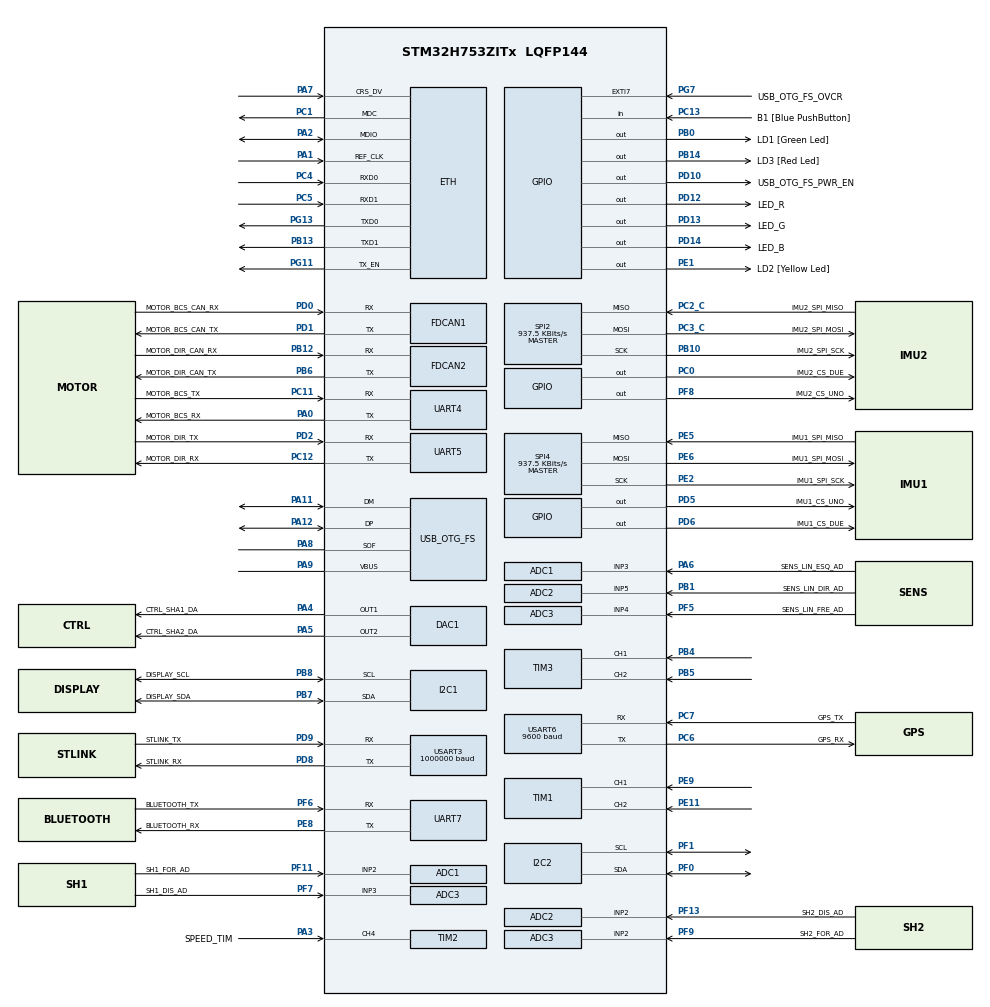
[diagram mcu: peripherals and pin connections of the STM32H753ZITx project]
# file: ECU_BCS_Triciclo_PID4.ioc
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ADC1.Channel-0\#ChannelRegularConversion=ADC_CHANNEL_2
ADC1.ClockPrescaler=ADC_CLOCK_ASYNC_DIV4
ADC1.NbrOfConversionFlag=1
ADC1.OffsetNumber-0\#ChannelRegularConversion=ADC_OFFSET_NONE
ADC1.OffsetSignedSaturation-0\#ChannelRegularConversion=DISABLE
ADC1.Rank-0\#ChannelRegularConversion=1
ADC1.SamplingTime-0\#ChannelRegularConversion=ADC_SAMPLETIME_1CYCLE_5
ADC1.master=1
ADC2.Channel-0\#ChannelRegularConversion=ADC_CHANNEL_2
ADC2.ClockPrescaler=ADC_CLOCK_ASYNC_DIV4
ADC2.NbrOfConversionFlag=1
ADC2.OffsetNumber-0\#ChannelRegularConversion=ADC_OFFSET_NONE
ADC2.OffsetSignedSaturation-0\#ChannelRegularConversion=DISABLE
ADC2.Rank-0\#ChannelRegularConversion=1
ADC2.SamplingTime-0\#ChannelRegularConversion=ADC_SAMPLETIME_1CYCLE_5
ADC3.Channel-0\#ChannelRegularConversion=ADC_CHANNEL_2
ADC3.ClockPrescaler=ADC_CLOCK_ASYNC_DIV4
ADC3.NbrOfConversionFlag=1
ADC3.OffsetNumber-0\#ChannelRegularConversion=ADC_OFFSET_NONE
ADC3.OffsetSignedSaturation-0\#ChannelRegularConversion=DISABLE
ADC3.Rank-0\#ChannelRegularConversion=1
ADC3.SamplingTime-0\#ChannelRegularConversion=ADC_SAMPLETIME_1CYCLE_5
CORTEX_M7.CPU_DCache=Disabled
CORTEX_M7.CPU_ICache=Disabled
CORTEX_M7.MPU_Control=__NULL
DAC1.DAC_Channel-DAC_OUT1=DAC_CHANNEL_1
DAC1.DAC_Channel-DAC_OUT2=DAC_CHANNEL_2
Dma.Request0=SPI4_RX
Dma.Request1=SPI4_TX
Dma.SPI4_RX.0.Direction=DMA_PERIPH_TO_MEMORY
Dma.SPI4_RX.0.EventEnable=DISABLE
Dma.SPI4_RX.0.FIFOMode=DMA_FIFOMODE_DISABLE
Dma.SPI4_RX.0.Instance=DMA1_Stream0
Dma.SPI4_RX.0.MemDataAlignment=DMA_MDATAALIGN_WORD
Dma.SPI4_RX.0.MemInc=DMA_MINC_ENABLE
Dma.SPI4_RX.0.Mode=DMA_NORMAL
Dma.SPI4_RX.0.PeriphDataAlignment=DMA_PDATAALIGN_WORD
Dma.SPI4_RX.0.PeriphInc=DMA_PINC_DISABLE
Dma.SPI4_RX.0.Polarity=HAL_DMAMUX_REQ_GEN_RISING
Dma.SPI4_RX.0.Priority=DMA_PRIORITY_LOW
Dma.SPI4_RX.0.RequestNumber=1
Dma.SPI4_RX.0.SignalID=NONE
Dma.SPI4_RX.0.SyncEnable=DISABLE
Dma.SPI4_RX.0.SyncPolarity=HAL_DMAMUX_SYNC_NO_EVENT
Dma.SPI4_RX.0.SyncRequestNumber=1
Dma.SPI4_RX.0.SyncSignalID=NONE
Dma.SPI4_TX.1.Direction=DMA_MEMORY_TO_PERIPH
Dma.SPI4_TX.1.EventEnable=DISABLE
Dma.SPI4_TX.1.FIFOMode=DMA_FIFOMODE_DISABLE
Dma.SPI4_TX.1.Instance=DMA1_Stream1
Dma.SPI4_TX.1.MemDataAlignment=DMA_MDATAALIGN_WORD
Dma.SPI4_TX.1.MemInc=DMA_MINC_ENABLE
Dma.SPI4_TX.1.Mode=DMA_NORMAL
Dma.SPI4_TX.1.PeriphDataAlignment=DMA_PDATAALIGN_WORD
Dma.SPI4_TX.1.PeriphInc=DMA_PINC_DISABLE
Dma.SPI4_TX.1.Polarity=HAL_DMAMUX_REQ_GEN_RISING
Dma.SPI4_TX.1.Priority=DMA_PRIORITY_LOW
Dma.SPI4_TX.1.RequestNumber=1
Dma.SPI4_TX.1.SignalID=NONE
Dma.SPI4_TX.1.SyncEnable=DISABLE
Dma.SPI4_TX.1.SyncPolarity=HAL_DMAMUX_SYNC_NO_EVENT
Dma.SPI4_TX.1.SyncRequestNumber=1
Dma.SPI4_TX.1.SyncSignalID=NONE
ETH.ETH_RX_DESC_CNT=4
ETH.ETH_TX_DESC_CNT=4
ETH.MACAddr=00\:80\:E1\:00\:00\:00
ETH.MediaInterface=HAL_ETH_RMII_MODE
ETH.RxBuffAddress=0x30040200
ETH.RxBuffLen=1524
ETH.RxDescAddress=0x30040000
ETH.TxDescAddress=0x30040060
FDCAN1.AutoRetransmission=DISABLE
FDCAN1.CalculateBaudRateNominal=250000
FDCAN1.CalculateTimeBitNominal=4000
FDCAN1.CalculateTimeQuantumNominal=250.0
FDCAN1.DataPrescaler=25
FDCAN1.DataSyncJumpWidth=1
FDCAN1.DataTimeSeg1=2
FDCAN1.DataTimeSeg2=1
FDCAN1.NominalPrescaler=20
FDCAN1.NominalSyncJumpWidth=13
FDCAN1.NominalTimeSeg1=13
FDCAN1.RxFifo0ElmtsNbr=6
FDCAN1.StdFiltersNbr=1
FDCAN1.TxBuffersNbr=0
FDCAN1.TxFifoQueueElmtsNbr=6
FDCAN1.TxFifoQueueMode=FDCAN_TX_FIFO_OPERATION
FDCAN2.AutoRetransmission=ENABLE
FDCAN2.CalculateBaudRateNominal=250000
FDCAN2.CalculateTimeBitNominal=4000
FDCAN2.CalculateTimeQuantumNominal=250.0
FDCAN2.DataPrescaler=25
FDCAN2.DataSyncJumpWidth=1
FDCAN2.DataTimeSeg1=2
FDCAN2.MessageRAMOffset=1024
FDCAN2.NominalPrescaler=20
FDCAN2.NominalSyncJumpWidth=13
FDCAN2.NominalTimeSeg1=13
FDCAN2.RxFifo0ElmtsNbr=1
FDCAN2.StdFiltersNbr=1
FDCAN2.TxBuffersNbr=0
FDCAN2.TxFifoQueueElmtsNbr=1
FREERTOS.Queues01=lcdMessageQueue,16,lcdMessage_t,0,Static,lcdMessageQueueBuffer,lcdMessageQueueControlBlock
FREERTOS.Tasks01=defaultTask,24,128,StartDefaultTask,As weak,NULL,Dynamic,NULL,NULL;sensorReadings,40,512,vSensorReadingsStart,As external,NULL,Static,sensorReadingsBuffer,sensorReadingsControlBlock;systemInit,54,1024,vSystemInitStart,As external,NULL,Static,systemInitBuffer,systemInitControlBlock;systemControl,48,1024,vSystemControlStart,As external,NULL,Static,systemControlBuffer,systemControlControlBlock;motorControl,50,1024,vMotorControlStart,As external,NULL,Static,motorControlBuffer,motorControlControlBlock;lcd,53,2048,vLcdStart,As external,NULL,Static,lcdBuffer,lcdControlBlock
FREERTOS.configENABLE_FPU=1
FREERTOS.configTOTAL_HEAP_SIZE=100000
FREERTOS.configUSE_NEWLIB_REENTRANT=1
I2C1.Timing=0x007074AF
I2C2.Timing=0x007074AF
Mcu.Family=STM32H7
Mcu.Name=STM32H753ZITx
Mcu.Package=LQFP144
Mcu.UserConstants=UPDATE_RATE_MS,10
NVIC.DMA1_Stream0_IRQn=true\:5\:0\:false\:false\:true\:true\:false\:true\:true
NVIC.DMA1_Stream1_IRQn=true\:5\:0\:false\:false\:true\:true\:false\:true\:true
NVIC.FDCAN1_IT0_IRQn=true\:5\:0\:false\:false\:true\:true\:true\:true\:true
NVIC.FDCAN2_IT0_IRQn=true\:5\:0\:false\:false\:true\:true\:true\:true\:true
NVIC.PriorityGroup=NVIC_PRIORITYGROUP_4
NVIC.SPI2_IRQn=true\:5\:0\:false\:false\:true\:true\:true\:true\:true
NVIC.SPI4_IRQn=true\:5\:0\:false\:false\:true\:true\:false\:true\:true
NVIC.TIM6_DAC_IRQn=true\:5\:0\:false\:false\:true\:true\:true\:true\:true
NVIC.TIM7_IRQn=true\:5\:0\:false\:false\:true\:true\:true\:true\:true
NVIC.TIM8_UP_TIM13_IRQn=true\:15\:0\:false\:false\:true\:false\:false\:true\:true
NVIC.TimeBase=TIM8_UP_TIM13_IRQn
NVIC.TimeBaseIP=TIM8
NVIC.UART4_IRQn=true\:5\:0\:false\:false\:true\:true\:true\:true\:true
NVIC.UART5_IRQn=true\:5\:0\:false\:false\:true\:true\:true\:true\:true
NVIC.UART7_IRQn=true\:5\:0\:false\:false\:true\:true\:true\:true\:true
NVIC.USART3_IRQn=true\:5\:0\:false\:false\:true\:true\:true\:true\:true
NVIC.USART6_IRQn=true\:5\:0\:false\:false\:true\:true\:true\:true\:true
PA0.GPIO_Label=MOTOR_BCS_RX
PA0.Mode=Asynchronous
PA0.Signal=UART4_TX
PA1.Mode=RMII
PA1.Signal=ETH_REF_CLK
PA11.Mode=Device_Only
PA11.Signal=USB_OTG_FS_DM
PA12.Mode=Device_Only
PA12.Signal=USB_OTG_FS_DP
PA2.Mode=RMII
PA2.Signal=ETH_MDIO
PA3.GPIO_Label=SPEED_TIM
PA3.Signal=S_TIM2_CH4
PA4.GPIO_Label=CTRL_SHA1_DA
PA4.Signal=COMP_DAC11_group
PA5.GPIO_Label=CTRL_SHA2_DA
PA5.Signal=COMP_DAC12_group
PA6.GPIO_Label=SENS_LIN_ESQ_AD
PA6.Signal=ADCx_INP3
PA7.Mode=RMII
PA7.Signal=ETH_CRS_DV
PA8.Mode=Activate_SOF_FS
PA8.Signal=USB_OTG_FS_SOF
PA9.Mode=Activate_VBUS
PA9.Signal=USB_OTG_FS_VBUS
PB0.GPIO_Label=LD1 [Green Led]
PB0.Signal=GPIO_Output
PB1.GPIO_Label=SENS_LIN_DIR_AD
PB1.Signal=ADCx_INP5
PB10.GPIO_Label=IMU2_SPI_SCK
PB10.Mode=Full_Duplex_Master
PB10.Signal=SPI2_SCK
PB12.GPIO_Label=MOTOR_DIR_CAN_RX
PB12.Mode=FDCAN_Activate
PB12.Signal=FDCAN2_RX
PB13.Mode=RMII
PB13.Signal=ETH_TXD1
PB14.GPIO_Label=LD3 [Red Led]
PB14.Signal=GPIO_Output
PB4\ (NJTRST).Signal=S_TIM3_CH1
PB5.Signal=S_TIM3_CH2
PB6.GPIO_Label=MOTOR_DIR_CAN_TX
PB6.Mode=FDCAN_Activate
PB6.Signal=FDCAN2_TX
PB7.GPIO_Label=DISPLAY_SDA
PB7.Mode=I2C
PB7.Signal=I2C1_SDA
PB8.GPIO_Label=DISPLAY_SCL
PB8.Mode=I2C
PB8.Signal=I2C1_SCL
PC0.GPIO_Label=IMU2_CS_DUE
PC0.Signal=GPIO_Output
PC1.Mode=RMII
PC1.Signal=ETH_MDC
PC11.GPIO_Label=MOTOR_BCS_TX
PC11.Mode=Asynchronous
PC11.Signal=UART4_RX
PC12.GPIO_Label=MOTOR_DIR_RX
PC12.Mode=Asynchronous
PC12.Signal=UART5_TX
PC13.GPIO_Label=B1 [Blue PushButton]
PC13.Signal=GPIO_Input
PC14-OSC32_IN\ (OSC32_IN).Mode=LSE-External-Oscillator
PC14-OSC32_IN\ (OSC32_IN).Signal=RCC_OSC32_IN
PC15-OSC32_OUT\ (OSC32_OUT).Mode=LSE-External-Oscillator
PC15-OSC32_OUT\ (OSC32_OUT).Signal=RCC_OSC32_OUT
PC2_C.GPIO_Label=IMU2_SPI_MISO
PC2_C.Mode=Full_Duplex_Master
PC2_C.Signal=SPI2_MISO
PC3_C.GPIO_Label=IMU2_SPI_MOSI
PC3_C.Mode=Full_Duplex_Master
PC3_C.Signal=SPI2_MOSI
PC4.Mode=RMII
PC4.Signal=ETH_RXD0
PC5.Mode=RMII
PC5.Signal=ETH_RXD1
PC6.GPIO_Label=GPS_RX
PC6.Mode=Asynchronous
PC6.Signal=USART6_TX
PC7.GPIO_Label=GPS_TX
PC7.Mode=Asynchronous
PC7.Signal=USART6_RX
PD0.GPIO_Label=MOTOR_BCS_CAN_RX
PD0.Mode=FDCAN_Activate
PD0.Signal=FDCAN1_RX
PD1.GPIO_Label=MOTOR_BCS_CAN_TX
PD1.Mode=FDCAN_Activate
PD1.Signal=FDCAN1_TX
PD10.GPIO_Label=USB_OTG_FS_PWR_EN
PD10.Signal=GPIO_Output
PD12.GPIO_Label=LED_R
PD12.Signal=GPIO_Output
PD13.GPIO_Label=LED_G
PD13.Signal=GPIO_Output
PD14.GPIO_Label=LED_B
PD14.Signal=GPIO_Output
PD2.GPIO_Label=MOTOR_DIR_TX
PD2.Mode=Asynchronous
PD2.Signal=UART5_RX
PD5.GPIO_Label=IMU1_CS_UNO
PD5.Signal=GPIO_Output
PD6.GPIO_Label=IMU1_CS_DUE
PD6.Signal=GPIO_Output
PD8.GPIO_Label=STLINK_RX
PD8.Mode=Asynchronous
PD8.Signal=USART3_TX
PD9.GPIO_Label=STLINK_TX
PD9.Mode=Asynchronous
PD9.Signal=USART3_RX
PE1.GPIO_Label=LD2 [Yellow Led]
PE1.Signal=GPIO_Output
PE11.Signal=S_TIM1_CH2
PE2.GPIO_Label=IMU1_SPI_SCK
PE2.Mode=Full_Duplex_Master
PE2.Signal=SPI4_SCK
PE5.GPIO_Label=IMU1_SPI_MISO
PE5.Mode=Full_Duplex_Master
PE5.Signal=SPI4_MISO
PE6.GPIO_Label=IMU1_SPI_MOSI
PE6.Mode=Full_Duplex_Master
PE6.Signal=SPI4_MOSI
PE8.GPIO_Label=BLUETOOTH_RX
PE8.Mode=Asynchronous
PE8.Signal=UART7_TX
PE9.Signal=S_TIM1_CH1
PF0.Mode=I2C
PF0.Signal=I2C2_SDA
PF1.Mode=I2C
PF1.Signal=I2C2_SCL
PF11.GPIO_Label=SH1_FOR_AD
PF11.Mode=IN2-Single-Ended
PF11.Signal=ADC1_INP2
PF13.GPIO_Label=SH2_DIS_AD
PF13.Mode=IN2-Single-Ended
PF13.Signal=ADC2_INP2
PF5.GPIO_Label=SENS_LIN_FRE_AD
PF5.Mode=IN4-Single-Ended
PF5.Signal=ADC3_INP4
PF6.GPIO_Label=BLUETOOTH_TX
PF6.Mode=Asynchronous
PF6.Signal=UART7_RX
PF7.GPIO_Label=SH1_DIS_AD
PF7.Mode=IN3-Single-Ended
PF7.Signal=ADC3_INP3
PF8.GPIO_Label=IMU2_CS_UNO
PF8.Signal=GPIO_Output
PF9.GPIO_Label=SH2_FOR_AD
PF9.Mode=IN2-Single-Ended
PF9.Signal=ADC3_INP2
PG11.Mode=RMII
PG11.Signal=ETH_TX_EN
PG13.Mode=RMII
PG13.Signal=ETH_TXD0
PG7.GPIO_Label=USB_OTG_FS_OVCR
PG7.Signal=GPXTI7
PH0-OSC_IN\ (PH0).Mode=HSE-External-Clock-Source
PH0-OSC_IN\ (PH0).Signal=RCC_OSC_IN
PH1-OSC_OUT\ (PH1).Signal=RCC_OSC_OUT
ProjectManager.HeapSize=0x200
ProjectManager.StackSize=0x400
ProjectManager.TargetToolchain=STM32CubeIDE
RCC.ADCCLockSelection=RCC_ADCCLKSOURCE_PLL3
RCC.ADCFreq_Value=120000000
RCC.APB1Freq_Value=30000000
RCC.APB2Freq_Value=30000000
RCC.APB3Freq_Value=120000000
RCC.APB4Freq_Value=120000000
RCC.CortexFreq_Value=480000000
RCC.D1PPRE=RCC_APB3_DIV2
RCC.D2PPRE1=RCC_APB1_DIV8
RCC.D2PPRE2=RCC_APB2_DIV8
RCC.D3PPRE=RCC_APB4_DIV2
RCC.DIVM1=1
RCC.DIVM2=1
RCC.DIVM3=2
RCC.DIVN1=120
RCC.DIVN2=120
RCC.DIVN3=60
RCC.DIVQ1=4
RCC.DIVQ2=12
RCC.FDCANCLockSelection=RCC_FDCANCLKSOURCE_PLL2
RCC.HCLKFreq_Value=240000000
RCC.HPRE=RCC_HCLK_DIV2
RCC.HSE_VALUE=8000000
RCC.PLLFRACN=0
RCC.PLLSourceVirtual=RCC_PLLSOURCE_HSE
RCC.PWR_Regulator_Voltage_Scale=PWR_REGULATOR_VOLTAGE_SCALE0
RCC.SPI123CLockSelection=RCC_SPI123CLKSOURCE_PLL3
RCC.SYSCLKFreq_VALUE=480000000
RCC.SYSCLKSource=RCC_SYSCLKSOURCE_PLLCLK
RCC.SupplySource=PWR_LDO_SUPPLY
RCC.USBCLockSelection=RCC_USBCLKSOURCE_HSI48
RCC.USBFreq_Value=48000000
SH.ADCx_INP3.0=ADC1_INP3,IN3-Single-Ended
SH.ADCx_INP5.0=ADC2_INP5,IN5-Single-Ended
SH.COMP_DAC11_group.0=DAC1_OUT1,DAC_OUT1
SH.COMP_DAC12_group.0=DAC1_OUT2,DAC_OUT2
SH.S_TIM1_CH1.0=TIM1_CH1,Encoder_Interface
SH.S_TIM1_CH2.0=TIM1_CH2,Encoder_Interface
SH.S_TIM2_CH4.0=TIM2_CH4,Input_Capture4_from_TI4
SH.S_TIM3_CH1.0=TIM3_CH1,Encoder_Interface
SH.S_TIM3_CH2.0=TIM3_CH2,Encoder_Interface
SPI2.BaudRatePrescaler=SPI_BAUDRATEPRESCALER_128
SPI2.CalculateBaudRate=937.5 KBits/s
SPI2.DataSize=SPI_DATASIZE_8BIT
SPI2.Direction=SPI_DIRECTION_2LINES
SPI2.Mode=SPI_MODE_MASTER
SPI2.NSSPMode=SPI_NSS_PULSE_DISABLE
SPI2.VirtualType=VM_MASTER
SPI4.BaudRatePrescaler=SPI_BAUDRATEPRESCALER_32
SPI4.CalculateBaudRate=937.5 KBits/s
SPI4.DataSize=SPI_DATASIZE_8BIT
SPI4.Direction=SPI_DIRECTION_2LINES
SPI4.Mode=SPI_MODE_MASTER
SPI4.NSSPMode=SPI_NSS_PULSE_DISABLE
SPI4.VirtualType=VM_MASTER
TIM2.Channel-Input_Capture4_from_TI4=TIM_CHANNEL_4
TIM6.Prescaler=60000-1
TIM7.Period=UPDATE_RATE_MS-1
TIM7.Prescaler=60000-1
USART3.AutoBaudRateEnableParam=UART_ADVFEATURE_AUTOBAUDRATE_DISABLE
USART3.BaudRate=1000000
USART3.ClockPrescaler=PRESCALER_DIV1
USART3.DMADisableonRxErrorParam=ADVFEATURE_DMA_ENABLEONRXERROR
USART3.DataInvertParam=ADVFEATURE_DATAINV_DISABLE
USART3.FIFOMode=FIFOMODE_ENABLE
USART3.MSBFirstParam=ADVFEATURE_MSBFIRST_DISABLE
USART3.Mode=MODE_TX_RX
USART3.OneBitSampling=UART_ONE_BIT_SAMPLE_DISABLE
USART3.OverSampling=UART_OVERSAMPLING_16
USART3.OverrunDisableParam=ADVFEATURE_OVERRUN_ENABLE
USART3.Parity=PARITY_NONE
USART3.RXFIFOThreshold=RXFIFO_THRESHOLD_1EIGHTHFULL
USART3.RxPinLevelInvertParam=ADVFEATURE_RXINV_DISABLE
USART3.StopBits=STOPBITS_1
USART3.SwapParam=ADVFEATURE_SWAP_DISABLE
USART3.TXFIFOThreshold=TXFIFO_THRESHOLD_1EIGHTHFULL
USART3.TxPinLevelInvertParam=ADVFEATURE_TXINV_DISABLE
USART3.VirtualMode-Asynchronous=VM_ASYNC
USART3.WordLength=WORDLENGTH_8B
USART6.BaudRate=9600
USART6.VirtualMode-Asynchronous=VM_ASYNC
USB_OTG_FS.Sof_enable=ENABLE
USB_OTG_FS.VirtualMode=Device_Only
USB_OTG_FS.battery_charging_enable=ENABLE
USB_OTG_FS.low_power_enable=DISABLE
USB_OTG_FS.lpm_enable=DISABLE
USB_OTG_FS.use_dedicated_ep1=DISABLE
USB_OTG_FS.vbus_sensing_enable=ENABLE
VP_FREERTOS_VS_CMSIS_V2.Mode=CMSIS_V2
VP_SYS_VS_tim8.Mode=TIM8
VP_TIM2_VS_ClockSourceINT.Mode=Internal
VP_TIM4_VS_ClockSourceINT.Mode=Internal
VP_TIM6_VS_ClockSourceINT.Mode=Enable_Timer
VP_TIM7_VS_ClockSourceINT.Mode=Enable_Timer
board=NUCLEO-H753ZI

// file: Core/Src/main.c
/* USER CODE BEGIN Header */
/**
  ******************************************************************************
  * @file           : main.c
  * @brief          : Main program body
  ******************************************************************************
  * @attention
  *
  * <h2><center>&copy; Copyright (c) 2022 STMicroelectronics.
  * All rights reserved.</center></h2>
  *
  * This software component is licensed by ST under BSD 3-Clause license,
  * the "License"; You may not use this file except in compliance with the
  * License. You may obtain a copy of the License at:
  *                        opensource.org/licenses/BSD-3-Clause
  *
  ******************************************************************************
  */
/* USER CODE END Header */
#include "main.h"
#include "cmsis_os.h"
#include "adc.h"
#include "dac.h"
#include "dma.h"
#include "eth.h"
#include "fdcan.h"
#include "i2c.h"
#include "spi.h"
#include "tim.h"
#include "usart.h"
#include "usb_otg.h"
#include "gpio.h"

/* USER CODE BEGIN Includes */
#include "systemInit.h"
/* USER CODE END Includes */

/* USER CODE BEGIN PV */
uint8_t uiRx;
/* USER CODE END PV */

void SystemClock_Config(void);
void PeriphCommonClock_Config(void);
void MX_FREERTOS_Init(void);

int main(void)
{

  /* MCU Configuration--------------------------------------------------------*/

  /* Reset of all peripherals, Initializes the Flash interface and the Systick. */
  HAL_Init();

  /* Configure the system clock */
  SystemClock_Config();

/* Configure the peripherals common clocks */
  PeriphCommonClock_Config();

  /* Initialize all configured peripherals */
  MX_GPIO_Init();
  MX_DMA_Init();
  MX_USART3_UART_Init();
  MX_USB_OTG_FS_PCD_Init();
  MX_TIM7_Init();
  MX_FDCAN1_Init();
  MX_ADC1_Init();
  MX_ADC2_Init();
  MX_ADC3_Init();
  MX_DAC1_Init();
  MX_FDCAN2_Init();
  MX_SPI2_Init();
  MX_TIM4_Init();
  MX_UART4_Init();
  MX_UART5_Init();
  MX_UART7_Init();
  MX_I2C1_Init();
  MX_SPI4_Init();
  MX_TIM2_Init();
  MX_USART6_UART_Init();
  MX_ETH_Init();
  MX_TIM1_Init();
  MX_TIM3_Init();
  MX_TIM6_Init();
  MX_I2C2_Init();
  /* USER CODE BEGIN 2 */
  HAL_UART_Receive_IT(&huart3, &uiRx, 1);
  HAL_UART_Receive_IT(&huart6, &uiRx, 1);
  /* USER CODE END 2 */

  /* Init scheduler */
  osKernelInitialize();  /* Call init function for freertos objects (in freertos.c) */
  MX_FREERTOS_Init();

  /* Start scheduler */
  osKernelStart();

  /* We should never get here as control is now taken by the scheduler */
  /* Infinite loop */
  while (1)
  {

  }
}

void SystemClock_Config(void)
{
  RCC_OscInitTypeDef RCC_OscInitStruct = {0};
  RCC_ClkInitTypeDef RCC_ClkInitStruct = {0};

  /** Supply configuration update enable
  */
  HAL_PWREx_ConfigSupply(PWR_LDO_SUPPLY);

  /** Configure the main internal regulator output voltage
  */
  __HAL_PWR_VOLTAGESCALING_CONFIG(PWR_REGULATOR_VOLTAGE_SCALE1);

  while(!__HAL_PWR_GET_FLAG(PWR_FLAG_VOSRDY)) {}

  __HAL_RCC_SYSCFG_CLK_ENABLE();
  __HAL_PWR_VOLTAGESCALING_CONFIG(PWR_REGULATOR_VOLTAGE_SCALE0);

  while(!__HAL_PWR_GET_FLAG(PWR_FLAG_VOSRDY)) {}

  /** Macro to configure the PLL clock source
  */
  __HAL_RCC_PLL_PLLSOURCE_CONFIG(RCC_PLLSOURCE_HSE);

  /** Initializes the RCC Oscillators according to the specified parameters
  * in the RCC_OscInitTypeDef structure.
  */
  RCC_OscInitStruct.OscillatorType = RCC_OSCILLATORTYPE_HSI48|RCC_OSCILLATORTYPE_HSE;
  RCC_OscInitStruct.HSEState = RCC_HSE_BYPASS;
  RCC_OscInitStruct.HSI48State = RCC_HSI48_ON;
  RCC_OscInitStruct.PLL.PLLState = RCC_PLL_ON;
  RCC_OscInitStruct.PLL.PLLSource = RCC_PLLSOURCE_HSE;
  RCC_OscInitStruct.PLL.PLLM = 1;
  RCC_OscInitStruct.PLL.PLLN = 120;
  RCC_OscInitStruct.PLL.PLLP = 2;
  RCC_OscInitStruct.PLL.PLLQ = 4;
  RCC_OscInitStruct.PLL.PLLR = 2;
  RCC_OscInitStruct.PLL.PLLRGE = RCC_PLL1VCIRANGE_3;
  RCC_OscInitStruct.PLL.PLLVCOSEL = RCC_PLL1VCOWIDE;
  RCC_OscInitStruct.PLL.PLLFRACN = 0;
  if (HAL_RCC_OscConfig(&RCC_OscInitStruct) != HAL_OK)
  {
    Error_Handler();
  }

  /** Initializes the CPU, AHB and APB buses clocks
  */
  RCC_ClkInitStruct.ClockType = RCC_CLOCKTYPE_HCLK|RCC_CLOCKTYPE_SYSCLK
                              |RCC_CLOCKTYPE_PCLK1|RCC_CLOCKTYPE_PCLK2
                              |RCC_CLOCKTYPE_D3PCLK1|RCC_CLOCKTYPE_D1PCLK1;
  RCC_ClkInitStruct.SYSCLKSource = RCC_SYSCLKSOURCE_PLLCLK;
  RCC_ClkInitStruct.SYSCLKDivider = RCC_SYSCLK_DIV1;
  RCC_ClkInitStruct.AHBCLKDivider = RCC_HCLK_DIV2;
  RCC_ClkInitStruct.APB3CLKDivider = RCC_APB3_DIV2;
  RCC_ClkInitStruct.APB1CLKDivider = RCC_APB1_DIV8;
  RCC_ClkInitStruct.APB2CLKDivider = RCC_APB2_DIV8;
  RCC_ClkInitStruct.APB4CLKDivider = RCC_APB4_DIV2;

  if (HAL_RCC_ClockConfig(&RCC_ClkInitStruct, FLASH_LATENCY_4) != HAL_OK)
  {
    Error_Handler();
  }
}

void PeriphCommonClock_Config(void)
{
  RCC_PeriphCLKInitTypeDef PeriphClkInitStruct = {0};

  /** Initializes the peripherals clock
  */
  PeriphClkInitStruct.PeriphClockSelection = RCC_PERIPHCLK_ADC|RCC_PERIPHCLK_SPI2
                              |RCC_PERIPHCLK_FDCAN;
  PeriphClkInitStruct.PLL2.PLL2M = 1;
  PeriphClkInitStruct.PLL2.PLL2N = 120;
  PeriphClkInitStruct.PLL2.PLL2P = 2;
  PeriphClkInitStruct.PLL2.PLL2Q = 12;
  PeriphClkInitStruct.PLL2.PLL2R = 2;
  PeriphClkInitStruct.PLL2.PLL2RGE = RCC_PLL2VCIRANGE_3;
  PeriphClkInitStruct.PLL2.PLL2VCOSEL = RCC_PLL2VCOWIDE;
  PeriphClkInitStruct.PLL2.PLL2FRACN = 0;
  PeriphClkInitStruct.PLL3.PLL3M = 2;
  PeriphClkInitStruct.PLL3.PLL3N = 60;
  PeriphClkInitStruct.PLL3.PLL3P = 2;
  PeriphClkInitStruct.PLL3.PLL3Q = 2;
  PeriphClkInitStruct.PLL3.PLL3R = 2;
  PeriphClkInitStruct.PLL3.PLL3RGE = RCC_PLL3VCIRANGE_2;
  PeriphClkInitStruct.PLL3.PLL3VCOSEL = RCC_PLL3VCOWIDE;
  PeriphClkInitStruct.PLL3.PLL3FRACN = 0;
  PeriphClkInitStruct.Spi123ClockSelection = RCC_SPI123CLKSOURCE_PLL3;
  PeriphClkInitStruct.FdcanClockSelection = RCC_FDCANCLKSOURCE_PLL2;
  PeriphClkInitStruct.AdcClockSelection = RCC_ADCCLKSOURCE_PLL3;
  if (HAL_RCCEx_PeriphCLKConfig(&PeriphClkInitStruct) != HAL_OK)
  {
    Error_Handler();
  }
}

void HAL_TIM_PeriodElapsedCallback(TIM_HandleTypeDef *htim)
{
  if (htim->Instance == TIM8) {
    HAL_IncTick();
  }
  /* USER CODE BEGIN Callback 1 */
  // htim7 is triggered with an rate of 10ms
  	if(htim == &htim7)
  	{

  	}
  	else if(htim == &htim6)
  		vCommunicationSendBroadcast();
  /* USER CODE END Callback 1 */
}

void Error_Handler(void)
{
  __disable_irq();
  while (1)
  {
  }
}

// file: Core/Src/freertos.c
/* USER CODE BEGIN Header */
/**
  ******************************************************************************
  * File Name          : freertos.c
  * Description        : Code for freertos applications
  ******************************************************************************
  * @attention
  *
  * Copyright (c) 2023 STMicroelectronics.
  * All rights reserved.
  *
  * This software is licensed under terms that can be found in the LICENSE file
  * in the root directory of this software component.
  * If no LICENSE file comes with this software, it is provided AS-IS.
  *
  ******************************************************************************
  */
/* USER CODE END Header */

#include "FreeRTOS.h"
#include "task.h"
#include "main.h"
#include "cmsis_os.h"

/* USER CODE BEGIN Includes */
#include "sensorReadings.h"
#include "lcd.h"
/* USER CODE END Includes */

typedef StaticTask_t osStaticThreadDef_t;
typedef StaticQueue_t osStaticMessageQDef_t;

/* Definitions for defaultTask */
osThreadId_t defaultTaskHandle;
const osThreadAttr_t defaultTask_attributes = {
  .name = "defaultTask",
  .stack_size = 128 * 4,
  .priority = (osPriority_t) osPriorityNormal,
};
/* Definitions for sensorReadings */
osThreadId_t sensorReadingsHandle;
uint32_t sensorReadingsBuffer[ 512 ];
osStaticThreadDef_t sensorReadingsControlBlock;
const osThreadAttr_t sensorReadings_attributes = {
  .name = "sensorReadings",
  .cb_mem = &sensorReadingsControlBlock,
  .cb_size = sizeof(sensorReadingsControlBlock),
  .stack_mem = &sensorReadingsBuffer[0],
  .stack_size = sizeof(sensorReadingsBuffer),
  .priority = (osPriority_t) osPriorityHigh,
};
/* Definitions for systemInit */
osThreadId_t systemInitHandle;
uint32_t systemInitBuffer[ 1024 ];
osStaticThreadDef_t systemInitControlBlock;
const osThreadAttr_t systemInit_attributes = {
  .name = "systemInit",
  .cb_mem = &systemInitControlBlock,
  .cb_size = sizeof(systemInitControlBlock),
  .stack_mem = &systemInitBuffer[0],
  .stack_size = sizeof(systemInitBuffer),
  .priority = (osPriority_t) osPriorityRealtime6,
};
/* Definitions for systemControl */
osThreadId_t systemControlHandle;
uint32_t systemControlBuffer[ 1024 ];
osStaticThreadDef_t systemControlControlBlock;
const osThreadAttr_t systemControl_attributes = {
  .name = "systemControl",
  .cb_mem = &systemControlControlBlock,
  .cb_size = sizeof(systemControlControlBlock),
  .stack_mem = &systemControlBuffer[0],
  .stack_size = sizeof(systemControlBuffer),
  .priority = (osPriority_t) osPriorityRealtime,
};
/* Definitions for motorControl */
osThreadId_t motorControlHandle;
uint32_t motorControlBuffer[ 1024 ];
osStaticThreadDef_t motorControlControlBlock;
const osThreadAttr_t motorControl_attributes = {
  .name = "motorControl",
  .cb_mem = &motorControlControlBlock,
  .cb_size = sizeof(motorControlControlBlock),
  .stack_mem = &motorControlBuffer[0],
  .stack_size = sizeof(motorControlBuffer),
  .priority = (osPriority_t) osPriorityRealtime2,
};
/* Definitions for lcd */
osThreadId_t lcdHandle;
uint32_t lcdBuffer[ 2048 ];
osStaticThreadDef_t lcdControlBlock;
const osThreadAttr_t lcd_attributes = {
  .name = "lcd",
  .cb_mem = &lcdControlBlock,
  .cb_size = sizeof(lcdControlBlock),
  .stack_mem = &lcdBuffer[0],
  .stack_size = sizeof(lcdBuffer),
  .priority = (osPriority_t) osPriorityRealtime5,
};
/* Definitions for lcdMessageQueue */
osMessageQueueId_t lcdMessageQueueHandle;
uint8_t lcdMessageQueueBuffer[ 16 * sizeof( lcdMessage_t ) ];
osStaticMessageQDef_t lcdMessageQueueControlBlock;
const osMessageQueueAttr_t lcdMessageQueue_attributes = {
  .name = "lcdMessageQueue",
  .cb_mem = &lcdMessageQueueControlBlock,
  .cb_size = sizeof(lcdMessageQueueControlBlock),
  .mq_mem = &lcdMessageQueueBuffer,
  .mq_size = sizeof(lcdMessageQueueBuffer)
};

void StartDefaultTask(void *argument);
extern void vSensorReadingsStart(void *argument);
extern void vSystemInitStart(void *argument);
extern void vSystemControlStart(void *argument);
extern void vMotorControlStart(void *argument);
extern void vLcdStart(void *argument);

void MX_FREERTOS_Init(void); /* (MISRA C 2004 rule 8.1) */

void MX_FREERTOS_Init(void) {

  /* Create the queue(s) */
  /* creation of lcdMessageQueue */
  lcdMessageQueueHandle = osMessageQueueNew (16, sizeof(lcdMessage_t), &lcdMessageQueue_attributes);

  /* Create the thread(s) */
  /* creation of defaultTask */
  defaultTaskHandle = osThreadNew(StartDefaultTask, NULL, &defaultTask_attributes);

  /* creation of sensorReadings */
  sensorReadingsHandle = osThreadNew(vSensorReadingsStart, NULL, &sensorReadings_attributes);

  /* creation of systemInit */
  systemInitHandle = osThreadNew(vSystemInitStart, NULL, &systemInit_attributes);

  /* creation of systemControl */
  systemControlHandle = osThreadNew(vSystemControlStart, NULL, &systemControl_attributes);

  /* creation of motorControl */
  motorControlHandle = osThreadNew(vMotorControlStart, NULL, &motorControl_attributes);

  /* creation of lcd */
  lcdHandle = osThreadNew(vLcdStart, NULL, &lcd_attributes);

}

__weak void StartDefaultTask(void *argument)
{
  for(;;)
  {
    osDelay(1);
  }
}
